# layer3_rx_model: IP-XACT component
VLNV IcronTechnologies:IcronTechnologies:layer3_rx_model:1.0

## Parameters
addr_width = 8
bus_width = 32

## Bus interfaces (logical=physical port)
default_map: slave AGNISYS:AGNISYS:APB:1.0, memory map layer3_rxmap
  pclk=pclk, presetn=presetn, psel=psel, penable=penable, pwrite=pwrite, pprot=pprot, pstrb=pstrb, pwdata=pwdata, paddr=paddr, pready=pready, prdata=prdata, pslverr=pslverr

## Ports
in pclk
in presetn
in psel
in penable
in pwrite
in pprot[2:0]
in pstrb[(bus_width div 8 )-1:0]
in pwdata[bus_width -1:0]
in paddr[addr_width -1:0]
out pready
out prdata[bus_width -1:0]
out pslverr
out layer3_rx_regsversion_major_r[7:0]
out layer3_rx_regsversion_minor_r[7:0]
out layer3_rx_regsversion_patch_r[7:0]
out layer3_rx_regseth_de_framer_config0_jumbo_lt_code_enb
out layer3_rx_regseth_de_framer_config0_jumbo_lt_code_jumbo_lt_code_r[15:0]
out layer3_rx_regseth_de_framer_stats0_rd2clr_config_rd_valid_out
out layer3_rx_regseth_de_framer_stats0_rd2clr_config_wr_valid_out
out layer3_rx_regseth_de_framer_stats0_out_eop_rd_valid_out
out layer3_rx_regseth_de_framer_stats0_out_sop_rd_valid_out
out layer3_rx_regseth_de_framer_stats0_non_eth_pkt_rd_valid_out
out layer3_rx_regsptp_guard_config0_fix_ptp_violations_enb
out layer3_rx_regsptp_guard_config0_fix_ptp_violations_activate_r
out layer3_rx_regsptp_guard_config0_max_cycles_enb
out layer3_rx_regsptp_guard_config0_max_cycles_max_cycle_mode_r[3:0]
out layer3_rx_regsptp_guard_config0_max_cycles_max_cycles_r[15:0]
out layer3_rx_regsptp_guard_stats0_rd2clr_config_rd_valid_out
out layer3_rx_regsptp_guard_stats0_rd2clr_config_wr_valid_out
out layer3_rx_regsptp_guard_stats0_missing_sop_err_rd_valid_out
out layer3_rx_regsptp_guard_stats0_missing_eop_err_rd_valid_out
out layer3_rx_regsptp_guard_stats0_max_cycle_err_rd_valid_out

## Address spaces and blocks
layer3_rxmap.layer3_rx: base 0x000, range 0x100, width 32

## Registers
Registers are 32-bit, read-only, reset 0x0 unless marked. A register's access mark holds for its fields unless they carry their own. Offsets are from the block's base; lines under a group give offsets from that group; [hi:lo] are bit positions; {n}, {i} and the like mark numbered series; 'fields as' and 'values as' point back to an identical list; <NAME> marks a mode.

## layer3_rxmap.layer3_rx — Layer 3 Registers
Base 0x00000000
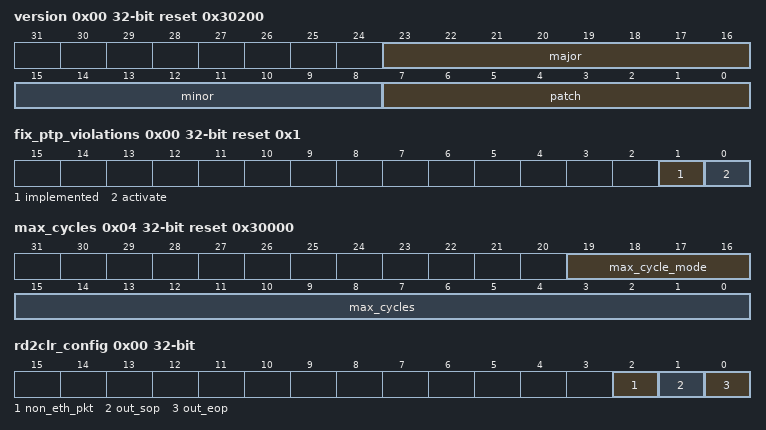
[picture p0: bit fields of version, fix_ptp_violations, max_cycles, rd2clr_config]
0x00 version reset 0x30200 — 3.1.0: Changed the Interrupt Pending to avoid blocking the register update when enable is 0 3.2.0: Added pending_irq register
  [23:16] major — Major version
  [15:8] minor — Minor version
  [7:0] patch — Patch version
0x04 eth_de_framer group
  0x00 version reset 0x10000
    fields as version
  0x04 config0 group
    0x00 jumbo_lt_code rw reset 0x1717 — Type code used for Jumbo Frames
      [15:0] jumbo_lt_code
  0x08 stats0 group — All the Statistic Registers and their configuration.
    0x00 rd2clr_config rw — Configures if the stats register read by s/w clears the read register. A 1 in any bit configures the h/w to clear the corresponding stats register after a s/w read of that stats register.
      [2] non_eth_pkt, [1] out_sop, [0] out_eop
    0x04 out_eop — Count of the PTP EOP seen on the output port
    0x08 out_sop — Count of the PTP SOP seen on the output port
    0x0C non_eth_pkt — Count of the Eth packets that the type is not supported
      [15:0] non_eth_pkt
0x1C ptp_guard group
  0x00 version reset 0x30300 — 3.1.0: Fixed bug in Max Cycle Error where in certain mode the cycles were included in the count 3.2.0: Changed the Interrupt Pending to avoid blocking the register update when enable is 0 3.3.0: Added pending_irq register
    fields as version
  0x04 config0 group
    0x00 fix_ptp_violations access per field reset 0x1
      [1] implemented ro — This is the synthesis parameter value used. When 1, it shows the PTP Guard fix logic has been implemented
      [0] activate rw — When 1, and if the fix logic is implemented, it instructs the PTP Guard to fix the PTP violations it detects (and reports). Note that there is a synthesis parameter to generate the "fix" logic or not When 0, no attempt is done to fix (even if the logic exists) and the PTP Guard will only work as a monitor and reports the violations detected. For full details of the operation, what violations are detected and fixed, and how the fix is done, see the wiki.
    0x04 max_cycles rw reset 0x30000
      [19:16] max_cycle_mode — This configures the mode of counting towards max_cycles: 0x0: All PTP cycles are included in the count 0x1: PTP cycles with backpressure (drdy=1'b0) are excluded from the count 0x2: PTP cycles with wait (srdy=1'b0) are excluded from the count 0x3: PTP cycles with either backpressure or wait are excluded from the count. Hence, only "absorbed" PTP cycles are included in the count Other mode values are reserved
      [15:0] max_cycles — Sets the maximum number of clock cycles the PTP packet can last between its sop and eop taking into account the max_cycle_mode When set to 0, it instructs the logic not to fix this violation (when the fix logic is available). However, the monitor will still issue a violation when the cycle count reaches its maximum and rollover.
  0x0C stats0 group — All the Statistic Registers and their configuration
    0x00 rd2clr_config rw — Configures if the stats register read by s/w clears the read register. A 1 in any bit configures the h/w to clear the corresponding stats register after a s/w read of that stats register.
      [2] max_cycle_err, [1] missing_eop_err, [0] missing_sop_err
    0x04 missing_sop_err — Counts the number of PTP violations due to missing sop where the srdy was asserted without a prior sop assertion
      [15:0] missing_sop_err
    0x08 missing_eop_err — Counts the number of PTP violations due to missing eop where the PTP had been started but a new sop is seen without ending the previously started PTP
      [15:0] missing_eop_err
    0x0C max_cycle_err — Counts the number of PTP violations due to reaching the maximum allowed cycles after starting a new PTP
      [15:0] max_cycle_err
  0x1C irq0 group — Define the IRQ group
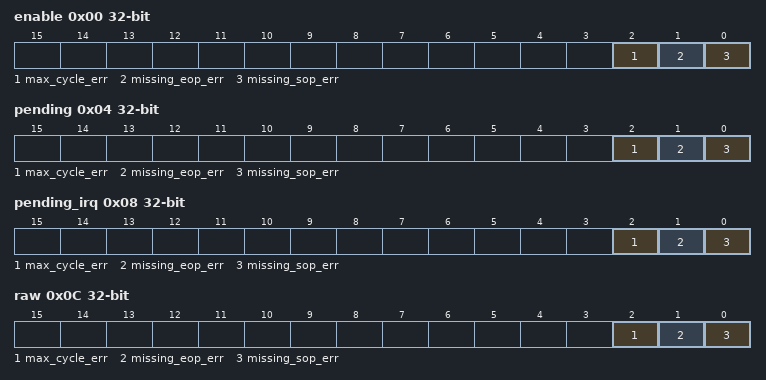
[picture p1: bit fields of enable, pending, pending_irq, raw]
    0x00 enable rw — The enable for the actual interrupt signals. Writing a 1 enables the interrupt.
      [2] max_cycle_err — Fires on PTP violations due to reaching the maximum allowed cycles after starting a new PTP
      [1] missing_eop_err — Fires on PTP violations due to missing eop where the PTP had been started but a new sop is seen without ending the previously started PTP
      [0] missing_sop_err — Fires on PTP violations due to missing sop where the srdy was asserted without a prior sop assertion
    0x04 pending rw — The actual interrupt(s) that has triggered. Write a 1 to clear.
      [2] max_cycle_err write-1-clears, [1] missing_eop_err write-1-clears, [0] missing_sop_err write-1-clears
    0x08 pending_irq — Registered version of pending & enable.
      [2] max_cycle_err, [1] missing_eop_err, [0] missing_sop_err
    0x0C raw — The status registered values for the interrupt signals, if applicable.
      [2] max_cycle_err — Not used
      [1] missing_eop_err — Not used
      [0] missing_sop_err — Not used
0x48 irq0 group — Define the IRQ group
  0x00 enable rw — Indicating a rollover for that particular count has occurred
    [2] de_framer_stats0_out_eop_irq_rollover, [1] de_framer_stats0_out_sop_irq_rollover, [0] de_framer_stats0_non_eth_pkt_irq_rollover
  0x04 pending rw — Indicating a rollover for that particular count has occurred
    [2] de_framer_stats0_out_eop_irq_rollover write-1-clears, [1] de_framer_stats0_out_sop_irq_rollover write-1-clears, [0] de_framer_stats0_non_eth_pkt_irq_rollover write-1-clears
  0x08 pending_irq — Registered version of pending & enable
    fields as irq0.enable
  0x0C raw — Indicating a rollover for that particular count has occurred
    fields as irq0.enable
